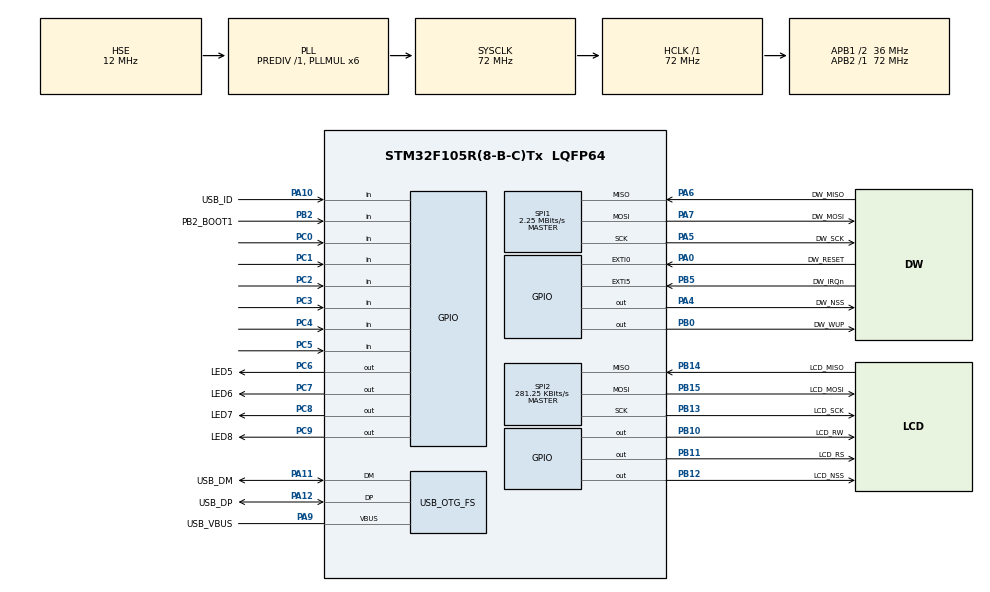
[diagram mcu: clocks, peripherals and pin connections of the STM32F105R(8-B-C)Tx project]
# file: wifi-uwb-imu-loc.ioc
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Mcu.Family=STM32F1
Mcu.Name=STM32F105R(8-B-C)Tx
Mcu.Package=LQFP64
NVIC.EXTI0_IRQn=true\:3\:0\:true\:true\:true\:1\:true\:true
NVIC.EXTI9_5_IRQn=true\:4\:0\:true\:true\:true\:2\:true\:true
NVIC.OTG_FS_IRQn=true\:7\:0\:true\:true\:true\:3\:true\:true
NVIC.PriorityGroup=NVIC_PRIORITYGROUP_4
NVIC.TIM2_IRQn=true\:0\:0\:false\:false\:true\:true\:true
PA0-WKUP.GPIO_Label=DW_RESET
PA0-WKUP.Signal=GPXTI0
PA10.GPIO_Label=USB_ID
PA10.Signal=GPIO_Input
PA11.GPIO_Label=USB_DM
PA11.Mode=Device_Only
PA11.Signal=USB_OTG_FS_DM
PA12.GPIO_Label=USB_DP
PA12.Mode=Device_Only
PA12.Signal=USB_OTG_FS_DP
PA13.GPIO_Label=J_TMS
PA13.Mode=JTAG_5_pins
PA13.Signal=SYS_JTMS-SWDIO
PA14.GPIO_Label=J_TCK
PA14.Mode=JTAG_5_pins
PA14.Signal=SYS_JTCK-SWCLK
PA15.GPIO_Label=J_TDI
PA15.Mode=JTAG_5_pins
PA15.Signal=SYS_JTDI
PA4.GPIO_Label=DW_NSS
PA4.GPIO_Speed=GPIO_SPEED_FREQ_HIGH
PA4.PinState=GPIO_PIN_SET
PA4.Signal=GPIO_Output
PA5.GPIO_Label=DW_SCK
PA5.Mode=Full_Duplex_Master
PA5.Signal=SPI1_SCK
PA6.GPIO_Label=DW_MISO
PA6.GPIO_PuPd=GPIO_PULLUP
PA6.Mode=Full_Duplex_Master
PA6.Signal=SPI1_MISO
PA7.GPIO_Label=DW_MOSI
PA7.Mode=Full_Duplex_Master
PA7.Signal=SPI1_MOSI
PA9.GPIO_Label=USB_VBUS
PA9.Mode=Activate_VBUS
PA9.Signal=USB_OTG_FS_VBUS
PB0.GPIO_Label=DW_WUP
PB0.GPIO_ModeDefaultOutputPP=GPIO_MODE_OUTPUT_OD
PB0.GPIO_Speed=GPIO_SPEED_FREQ_HIGH
PB0.PinState=GPIO_PIN_SET
PB0.Signal=GPIO_Output
PB10.GPIO_Label=LCD_RW
PB10.GPIO_Speed=GPIO_SPEED_FREQ_HIGH
PB10.Signal=GPIO_Output
PB11.GPIO_Label=LCD_RS
PB11.GPIO_Speed=GPIO_SPEED_FREQ_HIGH
PB11.Signal=GPIO_Output
PB12.GPIO_Label=LCD_NSS
PB12.GPIO_Speed=GPIO_SPEED_FREQ_HIGH
PB12.PinState=GPIO_PIN_SET
PB12.Signal=GPIO_Output
PB13.GPIO_Label=LCD_SCK
PB13.Mode=Full_Duplex_Master
PB13.Signal=SPI2_SCK
PB14.GPIO_Label=LCD_MISO
PB14.Mode=Full_Duplex_Master
PB14.Signal=SPI2_MISO
PB15.GPIO_Label=LCD_MOSI
PB15.Mode=Full_Duplex_Master
PB15.Signal=SPI2_MOSI
PB2.GPIO_Label=PB2_BOOT1
PB2.Signal=GPIO_Input
PB3.GPIO_Label=J_TDO
PB3.Mode=JTAG_5_pins
PB3.Signal=SYS_JTDO
PB4.GPIO_Label=J_TRST
PB4.Mode=JTAG_5_pins
PB4.Signal=SYS_NJTRST
PB5.GPIO_Label=DW_IRQn
PB5.GPIO_PuPd=GPIO_PULLDOWN
PB5.Signal=GPXTI5
PC0.Signal=GPIO_Input
PC1.Signal=GPIO_Input
PC2.Signal=GPIO_Input
PC3.Signal=GPIO_Input
PC4.Signal=GPIO_Input
PC5.Signal=GPIO_Input
PC6.GPIO_Label=LED5
PC6.GPIO_Speed=GPIO_SPEED_FREQ_HIGH
PC6.Signal=GPIO_Output
PC7.GPIO_Label=LED6
PC7.GPIO_Speed=GPIO_SPEED_FREQ_HIGH
PC7.Signal=GPIO_Output
PC8.GPIO_Label=LED7
PC8.GPIO_Speed=GPIO_SPEED_FREQ_HIGH
PC8.Signal=GPIO_Output
PC9.GPIO_Label=LED8
PC9.GPIO_Speed=GPIO_SPEED_FREQ_HIGH
PC9.Signal=GPIO_Output
PD0-OSC_IN.Mode=HSE-External-Oscillator
PD0-OSC_IN.Signal=RCC_OSC_IN
PD1-OSC_OUT.Mode=HSE-External-Oscillator
PD1-OSC_OUT.Signal=RCC_OSC_OUT
ProjectManager.HeapSize=0x200
ProjectManager.StackSize=0x400
ProjectManager.TargetToolchain=STM32CubeIDE
RCC.AHBFreq_Value=72000000
RCC.APB1CLKDivider=RCC_HCLK_DIV2
RCC.APB1Freq_Value=36000000
RCC.APB1TimFreq_Value=72000000
RCC.APB2Freq_Value=72000000
RCC.APB2TimFreq_Value=72000000
RCC.HCLKFreq_Value=72000000
RCC.HSE_VALUE=12000000
RCC.PLLMUL=RCC_PLL_MUL6
RCC.SYSCLKFreq_VALUE=72000000
RCC.SYSCLKSource=RCC_SYSCLKSOURCE_PLLCLK
RCC.USBFreq_Value=48000000
SPI1.BaudRatePrescaler=SPI_BAUDRATEPRESCALER_32
SPI1.CalculateBaudRate=2.25 MBits/s
SPI1.Direction=SPI_DIRECTION_2LINES
SPI1.Mode=SPI_MODE_MASTER
SPI1.VirtualType=VM_MASTER
SPI2.BaudRatePrescaler=SPI_BAUDRATEPRESCALER_128
SPI2.CLKPhase=SPI_PHASE_2EDGE
SPI2.CLKPolarity=SPI_POLARITY_HIGH
SPI2.CalculateBaudRate=281.25 KBits/s
SPI2.Direction=SPI_DIRECTION_2LINES
SPI2.Mode=SPI_MODE_MASTER
SPI2.VirtualType=VM_MASTER
TIM2.AutoReloadPreload=TIM_AUTORELOAD_PRELOAD_ENABLE
TIM2.Period=2000
TIM2.Prescaler=35999
USB_DEVICE.CLASS_NAME_FS=CDC
USB_DEVICE.USBD_HandleTypeDef=hUsbDeviceFS
USB_DEVICE.VirtualMode=Cdc
USB_DEVICE.VirtualModeFS=Cdc_FS
USB_OTG_FS.VirtualMode=Device_Only
VP_TIM2_VS_ClockSourceINT.Mode=Internal
VP_USB_DEVICE_VS_USB_DEVICE_CDC_FS.Mode=CDC_FS
board=EVK1000_CubeMX

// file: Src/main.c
/* USER CODE BEGIN Header */
/**
  ******************************************************************************
  * @file           : main.c
  * @brief          : Main program body
  ******************************************************************************
  * @attention
  *
  * <h2><center>&copy; Copyright (c) 2019 STMicroelectronics.
  * All rights reserved.</center></h2>
  *
  * This software component is licensed by ST under Ultimate Liberty license
  * SLA0044, the "License"; You may not use this file except in compliance with
  * the License. You may obtain a copy of the License at:
  *                             www.st.com/SLA0044
  *
  ******************************************************************************
  */
/* USER CODE END Header */

#include "main.h"
#include "usb_device.h"

/* USER CODE BEGIN Includes */
#include "tracking_application.h"
/* USER CODE END Includes */

SPI_HandleTypeDef hspi1;
SPI_HandleTypeDef hspi2;

TIM_HandleTypeDef htim2;

void SystemClock_Config(void);
static void MX_GPIO_Init(void);
static void MX_SPI1_Init(void);
static void MX_SPI2_Init(void);
static void MX_TIM2_Init(void);
static void MX_NVIC_Init(void);
/* USER CODE BEGIN PFP */
extern void (*tim2_handler)(void);
/* USER CODE END PFP */

int main(void)
{

  /* MCU Configuration--------------------------------------------------------*/

  /* Reset of all peripherals, Initializes the Flash interface and the Systick. */
  HAL_Init();

  /* Configure the system clock */
  SystemClock_Config();

  /* Initialize all configured peripherals */
  MX_GPIO_Init();
  MX_SPI1_Init();
  MX_SPI2_Init();
  MX_USB_DEVICE_Init();
  MX_TIM2_Init();

  /* Initialize interrupts */
  MX_NVIC_Init();
  /* USER CODE BEGIN 2 */
  tim2_handler = NULL;
  HAL_TIM_Base_Start_IT(&htim2);
  run_tracking_app();
  /* USER CODE END 2 */

  /* Infinite loop */
  while (1)
  {

  }
}

void SystemClock_Config(void)
{
  RCC_OscInitTypeDef RCC_OscInitStruct = {0};
  RCC_ClkInitTypeDef RCC_ClkInitStruct = {0};
  RCC_PeriphCLKInitTypeDef PeriphClkInit = {0};

  /** Initializes the CPU, AHB and APB busses clocks
  */
  RCC_OscInitStruct.OscillatorType = RCC_OSCILLATORTYPE_HSE;
  RCC_OscInitStruct.HSEState = RCC_HSE_ON;
  RCC_OscInitStruct.HSEPredivValue = RCC_HSE_PREDIV_DIV1;
  RCC_OscInitStruct.HSIState = RCC_HSI_ON;
  RCC_OscInitStruct.Prediv1Source = RCC_PREDIV1_SOURCE_HSE;
  RCC_OscInitStruct.PLL.PLLState = RCC_PLL_ON;
  RCC_OscInitStruct.PLL.PLLSource = RCC_PLLSOURCE_HSE;
  RCC_OscInitStruct.PLL.PLLMUL = RCC_PLL_MUL6;
  RCC_OscInitStruct.PLL2.PLL2State = RCC_PLL_NONE;
  if (HAL_RCC_OscConfig(&RCC_OscInitStruct) != HAL_OK)
  {
    Error_Handler();
  }
  /** Initializes the CPU, AHB and APB busses clocks
  */
  RCC_ClkInitStruct.ClockType = RCC_CLOCKTYPE_HCLK|RCC_CLOCKTYPE_SYSCLK
                              |RCC_CLOCKTYPE_PCLK1|RCC_CLOCKTYPE_PCLK2;
  RCC_ClkInitStruct.SYSCLKSource = RCC_SYSCLKSOURCE_PLLCLK;
  RCC_ClkInitStruct.AHBCLKDivider = RCC_SYSCLK_DIV1;
  RCC_ClkInitStruct.APB1CLKDivider = RCC_HCLK_DIV2;
  RCC_ClkInitStruct.APB2CLKDivider = RCC_HCLK_DIV1;

  if (HAL_RCC_ClockConfig(&RCC_ClkInitStruct, FLASH_LATENCY_2) != HAL_OK)
  {
    Error_Handler();
  }
  PeriphClkInit.PeriphClockSelection = RCC_PERIPHCLK_USB;
  PeriphClkInit.UsbClockSelection = RCC_USBCLKSOURCE_PLL_DIV3;
  if (HAL_RCCEx_PeriphCLKConfig(&PeriphClkInit) != HAL_OK)
  {
    Error_Handler();
  }
  /** Configure the Systick interrupt time
  */
  __HAL_RCC_PLLI2S_ENABLE();
}

/**
  * @brief NVIC Configuration.
  * @retval None
  */
static void MX_NVIC_Init(void)
{
  /* EXTI0_IRQn interrupt configuration */
  HAL_NVIC_SetPriority(EXTI0_IRQn, 3, 0);
  HAL_NVIC_EnableIRQ(EXTI0_IRQn);
  /* EXTI9_5_IRQn interrupt configuration */
  HAL_NVIC_SetPriority(EXTI9_5_IRQn, 4, 0);
  HAL_NVIC_EnableIRQ(EXTI9_5_IRQn);
  /* OTG_FS_IRQn interrupt configuration */
  HAL_NVIC_SetPriority(OTG_FS_IRQn, 7, 0);
  HAL_NVIC_EnableIRQ(OTG_FS_IRQn);
}

static void MX_SPI1_Init(void)
{

  /* SPI1 parameter configuration*/
  hspi1.Instance = SPI1;
  hspi1.Init.Mode = SPI_MODE_MASTER;
  hspi1.Init.Direction = SPI_DIRECTION_2LINES;
  hspi1.Init.DataSize = SPI_DATASIZE_8BIT;
  hspi1.Init.CLKPolarity = SPI_POLARITY_LOW;
  hspi1.Init.CLKPhase = SPI_PHASE_1EDGE;
  hspi1.Init.NSS = SPI_NSS_SOFT;
  hspi1.Init.BaudRatePrescaler = SPI_BAUDRATEPRESCALER_32;
  hspi1.Init.FirstBit = SPI_FIRSTBIT_MSB;
  hspi1.Init.TIMode = SPI_TIMODE_DISABLE;
  hspi1.Init.CRCCalculation = SPI_CRCCALCULATION_DISABLE;
  hspi1.Init.CRCPolynomial = 10;
  if (HAL_SPI_Init(&hspi1) != HAL_OK)
  {
    Error_Handler();
  }

}

static void MX_SPI2_Init(void)
{

  /* SPI2 parameter configuration*/
  hspi2.Instance = SPI2;
  hspi2.Init.Mode = SPI_MODE_MASTER;
  hspi2.Init.Direction = SPI_DIRECTION_2LINES;
  hspi2.Init.DataSize = SPI_DATASIZE_8BIT;
  hspi2.Init.CLKPolarity = SPI_POLARITY_HIGH;
  hspi2.Init.CLKPhase = SPI_PHASE_2EDGE;
  hspi2.Init.NSS = SPI_NSS_SOFT;
  hspi2.Init.BaudRatePrescaler = SPI_BAUDRATEPRESCALER_128;
  hspi2.Init.FirstBit = SPI_FIRSTBIT_MSB;
  hspi2.Init.TIMode = SPI_TIMODE_DISABLE;
  hspi2.Init.CRCCalculation = SPI_CRCCALCULATION_DISABLE;
  hspi2.Init.CRCPolynomial = 10;
  if (HAL_SPI_Init(&hspi2) != HAL_OK)
  {
    Error_Handler();
  }

}

static void MX_TIM2_Init(void)
{

  TIM_ClockConfigTypeDef sClockSourceConfig = {0};
  TIM_MasterConfigTypeDef sMasterConfig = {0};

  htim2.Instance = TIM2;
  htim2.Init.Prescaler = 35999;
  htim2.Init.CounterMode = TIM_COUNTERMODE_UP;
  htim2.Init.Period = 2000;
  htim2.Init.ClockDivision = TIM_CLOCKDIVISION_DIV1;
  htim2.Init.AutoReloadPreload = TIM_AUTORELOAD_PRELOAD_ENABLE;
  if (HAL_TIM_Base_Init(&htim2) != HAL_OK)
  {
    Error_Handler();
  }
  sClockSourceConfig.ClockSource = TIM_CLOCKSOURCE_INTERNAL;
  if (HAL_TIM_ConfigClockSource(&htim2, &sClockSourceConfig) != HAL_OK)
  {
    Error_Handler();
  }
  sMasterConfig.MasterOutputTrigger = TIM_TRGO_RESET;
  sMasterConfig.MasterSlaveMode = TIM_MASTERSLAVEMODE_DISABLE;
  if (HAL_TIMEx_MasterConfigSynchronization(&htim2, &sMasterConfig) != HAL_OK)
  {
    Error_Handler();
  }

}

static void MX_GPIO_Init(void)
{
  GPIO_InitTypeDef GPIO_InitStruct = {0};

  /* GPIO Ports Clock Enable */
  __HAL_RCC_GPIOC_CLK_ENABLE();
  __HAL_RCC_GPIOD_CLK_ENABLE();
  __HAL_RCC_GPIOA_CLK_ENABLE();
  __HAL_RCC_GPIOB_CLK_ENABLE();

  /*Configure GPIO pin Output Level */
  HAL_GPIO_WritePin(DW_NSS_GPIO_Port, DW_NSS_Pin, GPIO_PIN_SET);

  /*Configure GPIO pin Output Level */
  HAL_GPIO_WritePin(GPIOB, DW_WUP_Pin|LCD_NSS_Pin, GPIO_PIN_SET);

  /*Configure GPIO pin Output Level */
  HAL_GPIO_WritePin(GPIOB, LCD_RW_Pin|LCD_RS_Pin, GPIO_PIN_RESET);

  /*Configure GPIO pin Output Level */
  HAL_GPIO_WritePin(GPIOC, LED5_Pin|LED6_Pin|LED7_Pin|LED8_Pin, GPIO_PIN_RESET);

  /*Configure GPIO pins : PC13 PC14 PC15 PC10
                           PC11 PC12 */
  GPIO_InitStruct.Pin = GPIO_PIN_13|GPIO_PIN_14|GPIO_PIN_15|GPIO_PIN_10
                          |GPIO_PIN_11|GPIO_PIN_12;
  GPIO_InitStruct.Mode = GPIO_MODE_ANALOG;
  HAL_GPIO_Init(GPIOC, &GPIO_InitStruct);

  /*Configure GPIO pins : PC0 PC1 PC2 PC3
                           PC4 PC5 */
  GPIO_InitStruct.Pin = GPIO_PIN_0|GPIO_PIN_1|GPIO_PIN_2|GPIO_PIN_3
                          |GPIO_PIN_4|GPIO_PIN_5;
  GPIO_InitStruct.Mode = GPIO_MODE_INPUT;
  GPIO_InitStruct.Pull = GPIO_NOPULL;
  HAL_GPIO_Init(GPIOC, &GPIO_InitStruct);

  /*Configure GPIO pin : DW_RESET_Pin */
  GPIO_InitStruct.Pin = DW_RESET_Pin;
  GPIO_InitStruct.Mode = GPIO_MODE_IT_RISING;
  GPIO_InitStruct.Pull = GPIO_NOPULL;
  HAL_GPIO_Init(DW_RESET_GPIO_Port, &GPIO_InitStruct);

  /*Configure GPIO pins : PA1 PA2 PA3 PA8 */
  GPIO_InitStruct.Pin = GPIO_PIN_1|GPIO_PIN_2|GPIO_PIN_3|GPIO_PIN_8;
  GPIO_InitStruct.Mode = GPIO_MODE_ANALOG;
  HAL_GPIO_Init(GPIOA, &GPIO_InitStruct);

  /*Configure GPIO pin : DW_NSS_Pin */
  GPIO_InitStruct.Pin = DW_NSS_Pin;
  GPIO_InitStruct.Mode = GPIO_MODE_OUTPUT_PP;
  GPIO_InitStruct.Pull = GPIO_NOPULL;
  GPIO_InitStruct.Speed = GPIO_SPEED_FREQ_HIGH;
  HAL_GPIO_Init(DW_NSS_GPIO_Port, &GPIO_InitStruct);

  /*Configure GPIO pin : DW_WUP_Pin */
  GPIO_InitStruct.Pin = DW_WUP_Pin;
  GPIO_InitStruct.Mode = GPIO_MODE_OUTPUT_OD;
  GPIO_InitStruct.Pull = GPIO_NOPULL;
  GPIO_InitStruct.Speed = GPIO_SPEED_FREQ_HIGH;
  HAL_GPIO_Init(DW_WUP_GPIO_Port, &GPIO_InitStruct);

  /*Configure GPIO pins : PB1 PB6 PB7 PB8
                           PB9 */
  GPIO_InitStruct.Pin = GPIO_PIN_1|GPIO_PIN_6|GPIO_PIN_7|GPIO_PIN_8
                          |GPIO_PIN_9;
  GPIO_InitStruct.Mode = GPIO_MODE_ANALOG;
  HAL_GPIO_Init(GPIOB, &GPIO_InitStruct);

  /*Configure GPIO pin : PB2_BOOT1_Pin */
  GPIO_InitStruct.Pin = PB2_BOOT1_Pin;
  GPIO_InitStruct.Mode = GPIO_MODE_INPUT;
  GPIO_InitStruct.Pull = GPIO_NOPULL;
  HAL_GPIO_Init(PB2_BOOT1_GPIO_Port, &GPIO_InitStruct);

  /*Configure GPIO pins : LCD_RW_Pin LCD_RS_Pin LCD_NSS_Pin */
  GPIO_InitStruct.Pin = LCD_RW_Pin|LCD_RS_Pin|LCD_NSS_Pin;
  GPIO_InitStruct.Mode = GPIO_MODE_OUTPUT_PP;
  GPIO_InitStruct.Pull = GPIO_NOPULL;
  GPIO_InitStruct.Speed = GPIO_SPEED_FREQ_HIGH;
  HAL_GPIO_Init(GPIOB, &GPIO_InitStruct);

  /*Configure GPIO pins : LED5_Pin LED6_Pin LED7_Pin LED8_Pin */
  GPIO_InitStruct.Pin = LED5_Pin|LED6_Pin|LED7_Pin|LED8_Pin;
  GPIO_InitStruct.Mode = GPIO_MODE_OUTPUT_PP;
  GPIO_InitStruct.Pull = GPIO_NOPULL;
  GPIO_InitStruct.Speed = GPIO_SPEED_FREQ_HIGH;
  HAL_GPIO_Init(GPIOC, &GPIO_InitStruct);

  /*Configure GPIO pin : USB_ID_Pin */
  GPIO_InitStruct.Pin = USB_ID_Pin;
  GPIO_InitStruct.Mode = GPIO_MODE_INPUT;
  GPIO_InitStruct.Pull = GPIO_NOPULL;
  HAL_GPIO_Init(USB_ID_GPIO_Port, &GPIO_InitStruct);

  /*Configure GPIO pin : PD2 */
  GPIO_InitStruct.Pin = GPIO_PIN_2;
  GPIO_InitStruct.Mode = GPIO_MODE_ANALOG;
  HAL_GPIO_Init(GPIOD, &GPIO_InitStruct);

  /*Configure GPIO pin : DW_IRQn_Pin */
  GPIO_InitStruct.Pin = DW_IRQn_Pin;
  GPIO_InitStruct.Mode = GPIO_MODE_IT_RISING;
  GPIO_InitStruct.Pull = GPIO_PULLDOWN;
  HAL_GPIO_Init(DW_IRQn_GPIO_Port, &GPIO_InitStruct);

}

/* USER CODE BEGIN 4 */
//#include "port.h"
//static  int led_tog;
void HAL_TIM_PeriodElapsedCallback(TIM_HandleTypeDef *htim)
{
	if (htim->Instance == TIM2 )
	{
		if(tim2_handler != NULL)
			(*tim2_handler)();
//		if(led_tog%2==0)
//			led_on(LED_ALL);
//		else
//			led_off(LED_ALL);
//		++led_tog;
	}
}
/* USER CODE END 4 */

void Error_Handler(void)
{
}

/************************ (C) COPYRIGHT STMicroelectronics *****END OF FILE****/
